AUTOSAR XML (schema 00050)
package /SharedElements/ApplicationDataTypes/Array
  application array data type ApplicationArrayDataType_Fixed: category=ARRAY
    element Element: category=VALUE, type=ApplicationPrimitiveDataType, array-size-semantics=FIXED-SIZE, max-number-of-elements=15
  application array data type ApplicationArrayDataType_Variable: category=ARRAY, dynamic-array-size-profile=VSA_LINEAR
    element Element: category=VALUE, type=ApplicationPrimitiveDataType, array-size-handling=ALL-INDICES-SAME-ARRAY-SIZE, array-size-semantics=VARIABLE-SIZE, max-number-of-elements=15
package /SharedElements/ApplicationDataTypes/Primitive
  4 x app type, all with unit=NoUnit:
    ApplicationPrimitiveDataType: category=VALUE, compu {identical}, range phys 0..7, invalid-value=8
    Bool_ApplicationPrimitiveDataType: category=BOOLEAN, compu {identical}, range phys 0..7
    Copy_ApplicationPrimitiveDataType: category=VALUE, compu {identical}, range phys 0..7
    String_ApplicationPrimitiveDataType: category=STRING, sw-text-props={array-size-semantics=VARIABLE-SIZE, sw-max-text-size=16}
package /SharedElements/ApplicationDataTypes/Record
  application record data type ApplicationRecordDataType: category=STRUCTURE
    application record element Element: type=ApplicationPrimitiveDataType
    application record element Element1: type=ApplicationArrayDataType_Fixed
package /SharedElements/CompuMethods
  compu method BITFIELD_TEXTTABLE_CompuMethod: mask 0: 0=xyz, mask 0: 1=xyz1, mask 0: 2=xyz2, mask 0: 3=xyz3, mask 0: 4=xyz4
  compu method LINEAR_CompuMethod: phys=raw
  compu method RAT_FUNC_CompuMethod: phys=(0+1*raw+0*raw^2)/(1+0*raw+0*raw^2)
  compu method SCALE_RATIONAL_AND_TEXTTABLE_CompuMethod: phys=(0+1*raw+0*raw^2)/(1+0*raw+0*raw^2) for raw 0..15, 16=sdcd, 17=sdcd1, else 17
  compu method Scale_linear_And_texttable_CompuMethod: phys=raw for raw 0..7, 8=abcd, 9=abcd1, else 8  # Scale_linear _And_texttable_CompuMethod
  compu method TAB_NOINTP_CompuMethod: 0=10, 1=9, 2=8, else 0
  compu method TEXTTABLE_CompuMethod: 0..3=text1..text4, else 0
package /SharedElements/ConstantSpecifications
  4 x constant specification:
    ApplicationSwComponentType_ExplicitInterRunnableVariable: value-spec=Value:0
    ApplicationSwComponentType_SharedParameter: value-spec=Value:5.5
    ApplicationSwComponentType_StaticMemory: value-spec=Value:9
    ConstantSpecification
package /SharedElements/ConstantTypeMappingSets
  constant specification mapping set ConstantSpecificationMappingSet
package /SharedElements/DataTypemappingSets
  data type mapping set DataTypeMappingSet
    data-type-maps:
      application-data-type=ApplicationArrayDataType_Fixed, implementation-data-type=ARRAY_ImplementationDataType
      application-data-type=ApplicationRecordDataType, implementation-data-type=STRUCTURE_ImplementationDataType1
      application-data-type=ApplicationArrayDataType_Variable, implementation-data-type=Struct_Array_ImplementationDataType
      application-data-type=ApplicationPrimitiveDataType, implementation-data-type=uint16
package /SharedElements/ImplementationDataTypes
  6 x impl type:
    ARRAY_ImplementationDataType: category=ARRAY
      element SubElement: array-size=15, array-size-semantics=FIXED-SIZE, implementation-data-type=uint16
    ARRAY_ImplementationDataType1: category=ARRAY
      element SubElement: array-size=15, array-size-semantics=VARIABLE-SIZE, implementation-data-type=STRUCTURE_ImplementationDataType1
    ImplementationDataType: category=VALUE, base-type=uint8
    STRUCTURE_ImplementationDataType1: category=STRUCTURE
      element SubElement: implementation-data-type=uint16
      element SubElement1: implementation-data-type=ARRAY_ImplementationDataType
    Struct_Array_ImplementationDataType: category=STRUCTURE, dynamic-array-size-profile=VSA_LINEAR
      element SubElement1: implementation-data-type=uint8
      element SubElement: category=ARRAY
        element SubElement: array-size=15, array-size-handling=ALL-INDICES-SAME-ARRAY-SIZE, array-size-semantics=VARIABLE-SIZE, implementation-data-type=uint16
    TypeTref_ImplementationDataType: implementation-data-type=float32
package /SharedElements/PortInterfaces/ClientServer
  5 x client server interface:
    ClientServerInterface
      operation Operation
        arg Argument: type=ApplicationPrimitiveDataType, direction=IN, server-argument-impl-policy=USE-ARGUMENT-TYPE
      operation Operation1
        arg Argument: type=uint8, direction=OUT, server-argument-impl-policy=USE-ARGUMENT-TYPE
    Copy2_ClientServerInterface
      operation Operation
        arg Argument: type=ApplicationPrimitiveDataType, direction=IN, server-argument-impl-policy=USE-ARGUMENT-TYPE
      operation Operation1
        arg Argument: type=uint8, direction=OUT, server-argument-impl-policy=USE-ARGUMENT-TYPE
    Copy3_ClientServerInterface
      operation Operation
        arg Argument: type=ApplicationPrimitiveDataType, direction=IN, server-argument-impl-policy=USE-ARGUMENT-TYPE
      operation Operation1
        arg Argument: type=uint8, direction=OUT, server-argument-impl-policy=USE-ARGUMENT-TYPE
    Copy4_ClientServerInterface
      operation Operation
        arg Argument: type=ApplicationPrimitiveDataType, direction=IN, server-argument-impl-policy=USE-ARGUMENT-TYPE
      operation Operation1
        arg Argument: type=uint8, direction=OUT, server-argument-impl-policy=USE-ARGUMENT-TYPE
    Copy_ClientServerInterface
      operation Operation
        arg Argument: type=ApplicationPrimitiveDataType, direction=IN, server-argument-impl-policy=USE-ARGUMENT-TYPE
      operation Operation1
        arg Argument: type=uint8, direction=OUT, server-argument-impl-policy=USE-ARGUMENT-TYPE
package /SharedElements/PortInterfaces/ModeSwitch
  mode declaration group Copy_ModeDeclarationGroup: category=EXPLICIT_ORDER, initial-mode=Copy_ModeDeclarationGroup/ModeDeclaration, on-transition-value=3
    mode ModeDeclaration: value=0
    mode ModeDeclaration1: value=1
    mode ModeDeclaration2: value=2
  mode switch interface Copy_ModeSwitchInterface
    mode group ModeGroup: type=Copy_ModeDeclarationGroup
  mode declaration group ModeDeclarationGroup: category=ALPHABETIC_ORDER, initial-mode=ModeDeclarationGroup/ModeDeclaration
    mode ModeDeclaration
    mode ModeDeclaration1
    mode ModeDeclaration2
  mode switch interface ModeSwitchInterface
    mode group ModeGroup: type=ModeDeclarationGroup
package /SharedElements/PortInterfaces/NvData
  nv data interface NvDataInterface
    nv-datas:
      data NvData: type=uint8
      data NvData1: type=float64
package /SharedElements/PortInterfaces/Parameter
  parameter interface ParameterInterface
    parameter data prototype Parameter: sw-calibration-access=READ-WRITE, type=float32
    parameter data prototype Parameter1: sw-calibration-access=READ-WRITE, type=uint8
package /SharedElements/PortInterfaces/SenderReceiver
  6 x sender receiver interface:
    Copy2_SenderReceiverInterface
      data DataElement: sw-calibration-access=READ-WRITE, type=boolean
      data DataElement1: type=uint32
    Copy3_SenderReceiverInterface
      data DataElement: sw-calibration-access=READ-WRITE, type=boolean
      data DataElement1: type=uint32
    Copy4_SenderReceiverInterface
      data DataElement: sw-calibration-access=READ-WRITE, type=boolean
      data DataElement1: type=uint32
    Copy5_SenderReceiverInterface
      data DataElement: sw-calibration-access=READ-WRITE, type=boolean
      data DataElement1: type=uint32
    Copy_SenderReceiverInterface
      data DataElement: sw-calibration-access=READ-WRITE, type=boolean
      data DataElement1: type=uint32
    SenderReceiverInterface: invalidation-policy{data-element=SenderReceiverInterface/DataElement, handle-invalid=KEEP}
      data DataElement: sw-calibration-access=READ-WRITE, type=ApplicationPrimitiveDataType
      data DataElement1: type=uint32
package /SharedElements/PortInterfaces/Trigger
  trigger interface TriggerInterface
    trigger Trigger: trigger-period={cse-code=6, cse-code-factor=15}
package /SharedElements/SWCImpl
  swc implementation SwcImplementation: programming-language=C, sw-version=1.0.0.0, behavior=IB_Appl
    resource consumption ResourceConsumption
package /SharedElements/SwAddrMethods
  sw addr method Copy2_SwAddrMethod: memory-allocation-keyword-policy=ADDR-METHOD-SHORT-NAME, section-type=CODE
  sw addr method Copy_SwAddrMethod: memory-allocation-keyword-policy=ADDR-METHOD-SHORT-NAME-AND-ALIGNMENT, section-type=CALIBRATION-VARIABLES
  sw addr method SwAddrMethod: memory-allocation-keyword-policy=ADDR-METHOD-SHORT-NAME, section-type=CALIBRATION-VARIABLES
package /SwComponentTypes/ApplSWC
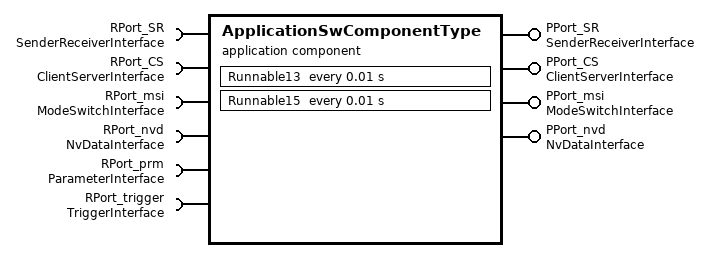
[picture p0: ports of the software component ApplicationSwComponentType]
  application sw component type ApplicationSwComponentType
    require port RPort_SR: required-interface=SenderReceiverInterface
    provide port PPort_SR: provided-interface=SenderReceiverInterface
    require port RPort_CS: required-interface=ClientServerInterface
    provide port PPort_CS: provided-interface=ClientServerInterface
    require port RPort_msi: required-interface=ModeSwitchInterface
    provide port PPort_msi: provided-interface=ModeSwitchInterface
    require port RPort_nvd: required-interface=NvDataInterface
    provide port PPort_nvd: provided-interface=NvDataInterface
    require port RPort_prm: required-interface=ParameterInterface
    require port RPort_trigger: required-interface=TriggerInterface
    behavior IB_Appl: data-type-mapping=DataTypeMappingSet, handle-termination-and-restart=NO-SUPPORT
      constant-memorys:
        parameter data prototype ConstantMemory: sw-calibration-access=READ-WRITE, type=uint64, init-value=Value:3
      static-memorys:
        data StaticMemory: type=uint8, init-value=constant-reference={short-label=ReferenceToConstant, constant=ApplicationSwComponentType_StaticMemory}
      ar-typed-per-instance-memorys:
        data ArTypedPerInstanceMemory: type=sint16, init-value=Value:-3
      asynchronous server call returns event AsynchronousServerCallReturnsEvent: start-on-event=Runnable, event-source=AsynchronousServerCallResultPoint
      background event BackgroundEvent: start-on-event=Runnable1
      data receive error event DataReceiveErrorEvent: start-on-event=Runnable2, data=RPort_SR.DataElement
      data received event DataReceivedEvent: start-on-event=Runnable3, data=RPort_SR.DataElement1
      data send completed event DataSendCompletedEvent: start-on-event=Runnable4, event-source=Runnable4/DSP_PPort_SR_DataElement
      data write completed event DataWriteCompletedEvent: start-on-event=Runnable5, event-source=Runnable5/DWA_PPort_SR_DataElement1
      external trigger occurred event ExternalTriggerOccurredEvent: start-on-event=Runnable6, trigger=RPort_trigger.Trigger
      init event InitEvent: start-on-event=Runnable7
      mode switched ack event ModeSwitchedAckEvent: start-on-event=Runnable9, event-source=Runnable9/MSP_PPort_msi_ModeGroup
      operation invoked event OperationInvokedEvent: start-on-event=Runnable10, operation=PPort_CS.Operation1
      swc mode manager error event SwcModeManagerErrorEvent: start-on-event=Runnable11, mode-group=PPort_msi.ModeGroup
      swc mode switch event SwcModeSwitchEvent: start-on-event=Runnable12, activation=ON-TRANSITION, mode=[RPort_msi.ModeGroup.ModeDeclaration2, RPort_msi.ModeGroup.ModeDeclaration]
      timing event TimingEvent: start-on-event=Runnable13, period=0.01
      transformer hard error event TransformerHardErrorEvent: start-on-event=Runnable14, required-trigger=RPort_trigger.Trigger
      timing event TimingEvent1: start-on-event=Runnable15, period=0.01
      explicit-inter-runnable-variables:
        data ExplicitInterRunnableVariable: type=boolean, init-value=constant-reference={short-label=ReferenceToConstant, constant=ApplicationSwComponentType_ExplicitInterRunnableVariable}
      implicit-inter-runnable-variables:
        data ImplicitInterRunnableVariable: type=sint16, init-value=Value:0
      per-instance-parameters:
        parameter data prototype PerInstanceParameter: sw-calibration-access=READ-WRITE, type=uint8, init-value=Value:5
      15 x runnable:
        Runnable: sw-addr-method=Copy2_SwAddrMethod, symbol=ApplicationSwComponentType_Runnable
          asynchronous server call result point AsynchronousServerCallResultPoint: asynchronous-server-call-point=ASCP_RPort_CS_Operation
          async call ASCP_RPort_CS_Operation: operation=RPort_CS.Operation, timeout=0
        Runnable{1..3}: symbol=ApplicationSwComponentType_Runnable{1..3}
        Runnable4: symbol=ApplicationSwComponentType_Runnable4
          data-send-points:
            access DSP_PPort_SR_DataElement: accessed-variable=PPort_SR.DataElement
        Runnable5: symbol=ApplicationSwComponentType_Runnable5
          data-write-access:
            access DWA_PPort_SR_DataElement1: accessed-variable=PPort_SR.DataElement1
        Runnable6: symbol=ApplicationSwComponentType_Runnable6
        Runnable7: symbol=ApplicationSwComponentType_Runnable7
        Runnable9: symbol=ApplicationSwComponentType_Runnable9
          mode switch point MSP_PPort_msi_ModeGroup: mode-group=PPort_msi.ModeGroup
        Runnable{10..12}: symbol=ApplicationSwComponentType_Runnable{10..12}
        Runnable13: symbol=ApplicationSwComponentType_Runnable13
          data-read-access:
            4 x access:
              DRA_RPort_SR_DataElement: accessed-variable=RPort_SR.DataElement
              DRA_RPort_SR_DataElement1: accessed-variable=RPort_SR.DataElement1
              DRA_RPort_nvd_NvData: accessed-variable=RPort_nvd.NvData
              DRA_RPort_nvd_NvData1: accessed-variable=RPort_nvd.NvData1
          data-write-access:
            4 x access:
              DWA_PPort_SR_DataElement: accessed-variable=PPort_SR.DataElement
              DWA_PPort_SR_DataElement1: accessed-variable=PPort_SR.DataElement1
              DWA_PPort_nvd_NvData: accessed-variable=PPort_nvd.NvData
              DWA_PPort_nvd_NvData1: accessed-variable=PPort_nvd.NvData1
          read-local-variables:
            access IRVRA_ExplicitInterRunnableVariable: accessed-variable=ExplicitInterRunnableVariable
            access IRVRA_ImplicitInterRunnableVariable: accessed-variable=ImplicitInterRunnableVariable
        Runnable14: symbol=ApplicationSwComponentType_Runnable14
        Runnable15: symbol=ApplicationSwComponentType_Runnable15
          data-read-access:
            access DRA_RPort_nvd_NvData: accessed-variable=RPort_nvd.NvData
            access DRA_RPort_nvd_NvData1: accessed-variable=RPort_nvd.NvData1
          data-receive-point-by-arguments:
            access DRP_RPort_SR_DataElement: accessed-variable=RPort_SR.DataElement
            access DRP_RPort_nvd_NvData: accessed-variable=RPort_nvd.NvData
            access DRP_RPort_nvd_NvData1: accessed-variable=RPort_nvd.NvData1
          data-receive-point-by-values:
            access DRPV_RPort_SR_DataElement1: accessed-variable=RPort_SR.DataElement1
            access DRPV_RPort_nvd_NvData: accessed-variable=RPort_nvd.NvData
          data-send-points:
            4 x access:
              DSP_PPort_SR_DataElement: accessed-variable=PPort_SR.DataElement
              DSP_PPort_SR_DataElement1: accessed-variable=PPort_SR.DataElement1
              DSP_PPort_nvd_NvData: accessed-variable=PPort_nvd.NvData
              DSP_PPort_nvd_NvData1: accessed-variable=PPort_nvd.NvData1
          data-write-access:
            access DWA_PPort_SR_DataElement1: accessed-variable=PPort_SR.DataElement1
          mode switch point MSP_PPort_msi_ModeGroup: mode-group=PPort_msi.ModeGroup
          5 x parameter access:
            ParameterAccess: accessed-parameter=ConstantMemory
            PICPVA_PerInstanceParameter: accessed-parameter=PerInstanceParameter
            CPA_RPort_prm_Parameter: accessed-parameter=RPort_prm.Parameter
            CPA_RPort_prm_Parameter1: accessed-parameter=RPort_prm.Parameter1
            SCPVA_SharedParameter: accessed-parameter=SharedParameter
          sync call SSCP_RPort_CS_Operation1: operation=RPort_CS.Operation1, timeout=0
          written-local-variables:
            access IRVWA_ExplicitInterRunnableVariable: accessed-variable=ExplicitInterRunnableVariable
            access IRVWA_ImplicitInterRunnableVariable: accessed-variable=ImplicitInterRunnableVariable
      shared-parameters:
        parameter data prototype SharedParameter: sw-calibration-access=READ-WRITE, type=float32, init-value=constant-reference={short-label=ReferenceToConstant, constant=ApplicationSwComponentType_SharedParameter}
package /SwComponentTypes/CddSWC
  complex device driver sw component type ComplexDeviceDriverSwComponentType
package /SwComponentTypes/CompSWC
  composition sw component type CompositionSwComponentType
package /SwComponentTypes/EcuAbSWC
  ecu abstraction sw component type EcuAbstractionSwComponentType
package /SwComponentTypes/NvDataSWC
  nv block sw component type NvBlockSwComponentType
package /SwComponentTypes/PrmSWC
  parameter sw component type ParameterSwComponentType
package /SwComponentTypes/SnsrActSWC
  sensor actuator sw component type SensorActuatorSwComponentType
package /SwComponentTypes/SrvcPrxySWC
  service proxy sw component type ServiceProxySwComponentType
package /SwComponentTypes/SrvcSWC
  service sw component type ServiceSwComponentType
